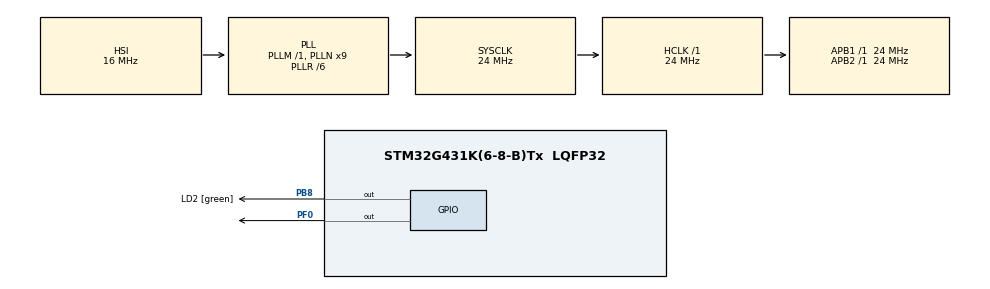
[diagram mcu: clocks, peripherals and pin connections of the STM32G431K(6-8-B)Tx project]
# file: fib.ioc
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Mcu.Family=STM32G4
Mcu.Name=STM32G431K(6-8-B)Tx
Mcu.Package=LQFP32
NVIC.PriorityGroup=NVIC_PRIORITYGROUP_4
NVIC.RTC_WKUP_IRQn=true\:0\:0\:false\:false\:true\:true\:true\:true
PA13.GPIO_Label=T_SWDIO
PA13.Mode=Serial_Wire
PA13.Signal=SYS_JTMS-SWDIO
PA14.GPIO_Label=T_SWCLK
PA14.Mode=Serial_Wire
PA14.Signal=SYS_JTCK-SWCLK
PA2.GPIO_Label=USART2_TX [ST-LINKV3E_VCP_RX]
PA2.Signal=USART2_TX
PA3.GPIO_Label=USART2_RX [ST-LINKV3E_VCP_TX]
PA3.Signal=USART2_RX
PB3.GPIO_Label=T_SWO
PB3.Signal=SYS_JTDO-SWO
PB8-BOOT0.GPIO_Label=LD2 [green]
PB8-BOOT0.Signal=GPIO_Output
PF0-OSC_IN.Signal=GPIO_Output
ProjectManager.HeapSize=0x200
ProjectManager.StackSize=0x400
ProjectManager.TargetToolchain=STM32CubeIDE
RCC.ADC12Freq_Value=24000000
RCC.AHBFreq_Value=24000000
RCC.APB1Freq_Value=24000000
RCC.APB1TimFreq_Value=24000000
RCC.APB2Freq_Value=24000000
RCC.APB2TimFreq_Value=24000000
RCC.CortexFreq_Value=24000000
RCC.EXTERNAL_CLOCK_VALUE=12288000
RCC.HCLKFreq_Value=24000000
RCC.HSE_VALUE=8000000
RCC.HSI48_VALUE=48000000
RCC.HSI_VALUE=16000000
RCC.LSE_VALUE=32768
RCC.PLLN=9
RCC.PLLR=RCC_PLLR_DIV6
RCC.SYSCLKFreq_VALUE=24000000
RCC.SYSCLKSource=RCC_SYSCLKSOURCE_PLLCLK
RCC.USBFreq_Value=72000000
RCC.VCOOutputFreq_Value=144000000
VP_RTC_VS_RTC_Activate.Mode=RTC_Enabled
VP_RTC_VS_RTC_WakeUp_intern.Mode=WakeUp
board=NUCLEO-G431KB

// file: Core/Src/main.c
/* USER CODE BEGIN Header */
/**
  ******************************************************************************
  * @file           : main.c
  * @brief          : Main program body
  ******************************************************************************
  * @attention
  *
  * Copyright (c) 2023 STMicroelectronics.
  * All rights reserved.
  *
  * This software is licensed under terms that can be found in the LICENSE file
  * in the root directory of this software component.
  * If no LICENSE file comes with this software, it is provided AS-IS.
  *
  ******************************************************************************
  */
/* USER CODE END Header */
#include "main.h"

RTC_HandleTypeDef hrtc;

void SystemClock_Config(void);
static void MX_GPIO_Init(void);
static void MX_RTC_Init(void);
/* USER CODE BEGIN PFP */
void SystemClock_Config170MHZ(void);
void SystemClock_Config150MHZ(void);
/* USER CODE END PFP */

/* USER CODE BEGIN 0 */

/*
void Sleep(int time)
{
    HAL_SuspendTick();
    uint32_t counter = time*2;
    HAL_RTCEx_SetWakeUpTimer_IT(&hrtc, counter, RTC_WAKEUPCLOCK_RTCCLK_DIV16);
    HAL_PWR_EnterSLEEPMode(PWR_MAINREGULATOR_ON, PWR_STOPENTRY_WFI);
    HAL_RTCEx_DeactivateWakeUpTimer(&hrtc);
    HAL_ResumeTick();
}*/

void EnterSleep()
{
    HAL_SuspendTick();
    HAL_PWR_EnterSLEEPMode(PWR_MAINREGULATOR_ON, PWR_STOPENTRY_WFI);
}

void fibonacci(unsigned int n)  {
    unsigned long long a = 0;
    unsigned long long b = 1;
    unsigned long long fib;

    for (unsigned int i = 2; i <= n; ++i) {
        fib = a + b;
        a = b;
        b = fib;
    }
}

__attribute__((section(".ccmram")))
void fibonacci_ccm(unsigned int n)  {
    unsigned long long a = 0;
    unsigned long long b = 1;
    unsigned long long fib;

    for (unsigned int i = 2; i <= n; ++i) {
        fib = a + b;
        a = b;
        b = fib;
    }
}

void Sleep(int time)
{
  HAL_SuspendTick();
  uint32_t counter = time*2;/*divide by (16/32)*/
  HAL_RTCEx_SetWakeUpTimer_IT(&hrtc, counter, RTC_WAKEUPCLOCK_RTCCLK_DIV16);

  /* Enter sleep mode */
  HAL_PWR_EnterSLEEPMode(PWR_MAINREGULATOR_ON, PWR_STOPENTRY_WFI);
  HAL_RTCEx_DeactivateWakeUpTimer(&hrtc);
  HAL_ResumeTick();
}
/* USER CODE END 0 */

int main(void)
{

  /* MCU Configuration--------------------------------------------------------*/

  /* Reset of all peripherals, Initializes the Flash interface and the Systick. */
  HAL_Init();

  /* Configure the system clock */
  SystemClock_Config();

  /* Initialize all configured peripherals */
  MX_GPIO_Init();
  MX_RTC_Init();

  /* Infinite loop */
  /* USER CODE BEGIN WHILE */
  int n = 500000;
  Sleep(500);
  fibonacci(n);
  Sleep(500);
  fibonacci_ccm(n);
  EnterSleep();

  /* USER CODE BEGIN SysInit */

  /* USER CODE END SysInit */

  /* Initialize all configured peripherals */

  /* USER CODE BEGIN 2 */
  /* USER CODE END 2 */

  /* Infinite loop */
  /* USER CODE BEGIN WHILE */

    /* USER CODE END WHILE */

}

void SystemClock_Config(void)
{
  RCC_OscInitTypeDef RCC_OscInitStruct = {0};
  RCC_ClkInitTypeDef RCC_ClkInitStruct = {0};

  /** Configure the main internal regulator output voltage
  */
  HAL_PWREx_ControlVoltageScaling(PWR_REGULATOR_VOLTAGE_SCALE1);

  /** Initializes the RCC Oscillators according to the specified parameters
  * in the RCC_OscInitTypeDef structure.
  */
  RCC_OscInitStruct.OscillatorType = RCC_OSCILLATORTYPE_HSI|RCC_OSCILLATORTYPE_LSI;
  RCC_OscInitStruct.HSIState = RCC_HSI_ON;
  RCC_OscInitStruct.HSICalibrationValue = RCC_HSICALIBRATION_DEFAULT;
  RCC_OscInitStruct.LSIState = RCC_LSI_ON;
  RCC_OscInitStruct.PLL.PLLState = RCC_PLL_ON;
  RCC_OscInitStruct.PLL.PLLSource = RCC_PLLSOURCE_HSI;
  RCC_OscInitStruct.PLL.PLLM = RCC_PLLM_DIV1;
  RCC_OscInitStruct.PLL.PLLN = 9;
  RCC_OscInitStruct.PLL.PLLP = RCC_PLLP_DIV2;
  RCC_OscInitStruct.PLL.PLLQ = RCC_PLLQ_DIV2;
  RCC_OscInitStruct.PLL.PLLR = RCC_PLLR_DIV6;
  if (HAL_RCC_OscConfig(&RCC_OscInitStruct) != HAL_OK)
  {
    Error_Handler();
  }

  /** Initializes the CPU, AHB and APB buses clocks
  */
  RCC_ClkInitStruct.ClockType = RCC_CLOCKTYPE_HCLK|RCC_CLOCKTYPE_SYSCLK
                              |RCC_CLOCKTYPE_PCLK1|RCC_CLOCKTYPE_PCLK2;
  RCC_ClkInitStruct.SYSCLKSource = RCC_SYSCLKSOURCE_PLLCLK;
  RCC_ClkInitStruct.AHBCLKDivider = RCC_SYSCLK_DIV1;
  RCC_ClkInitStruct.APB1CLKDivider = RCC_HCLK_DIV1;
  RCC_ClkInitStruct.APB2CLKDivider = RCC_HCLK_DIV1;

  if (HAL_RCC_ClockConfig(&RCC_ClkInitStruct, FLASH_LATENCY_0) != HAL_OK)
  {
    Error_Handler();
  }
}

static void MX_RTC_Init(void)
{

  /** Initialize RTC Only
  */
  hrtc.Instance = RTC;
  hrtc.Init.HourFormat = RTC_HOURFORMAT_24;
  hrtc.Init.AsynchPrediv = 127;
  hrtc.Init.SynchPrediv = 255;
  hrtc.Init.OutPut = RTC_OUTPUT_DISABLE;
  hrtc.Init.OutPutRemap = RTC_OUTPUT_REMAP_NONE;
  hrtc.Init.OutPutPolarity = RTC_OUTPUT_POLARITY_HIGH;
  hrtc.Init.OutPutType = RTC_OUTPUT_TYPE_OPENDRAIN;
  hrtc.Init.OutPutPullUp = RTC_OUTPUT_PULLUP_NONE;
  if (HAL_RTC_Init(&hrtc) != HAL_OK)
  {
    Error_Handler();
  }

  /** Enable the WakeUp
  */
  if (HAL_RTCEx_SetWakeUpTimer_IT(&hrtc, 0, RTC_WAKEUPCLOCK_RTCCLK_DIV16) != HAL_OK)
  {
    Error_Handler();
  }

}

static void MX_GPIO_Init(void)
{
  GPIO_InitTypeDef GPIO_InitStruct = {0};

  /* GPIO Ports Clock Enable */
  __HAL_RCC_GPIOF_CLK_ENABLE();
  __HAL_RCC_GPIOG_CLK_ENABLE();
  __HAL_RCC_GPIOA_CLK_ENABLE();
  __HAL_RCC_GPIOB_CLK_ENABLE();

  /*Configure GPIO pin Output Level */
  HAL_GPIO_WritePin(GPIOF, GPIO_PIN_0, GPIO_PIN_RESET);

  /*Configure GPIO pin Output Level */
  HAL_GPIO_WritePin(LD2_GPIO_Port, LD2_Pin, GPIO_PIN_RESET);

  /*Configure GPIO pin : PF0 */
  GPIO_InitStruct.Pin = GPIO_PIN_0;
  GPIO_InitStruct.Mode = GPIO_MODE_OUTPUT_PP;
  GPIO_InitStruct.Pull = GPIO_NOPULL;
  GPIO_InitStruct.Speed = GPIO_SPEED_FREQ_LOW;
  HAL_GPIO_Init(GPIOF, &GPIO_InitStruct);

  /*Configure GPIO pin : PF1 */
  GPIO_InitStruct.Pin = GPIO_PIN_1;
  GPIO_InitStruct.Mode = GPIO_MODE_ANALOG;
  GPIO_InitStruct.Pull = GPIO_NOPULL;
  HAL_GPIO_Init(GPIOF, &GPIO_InitStruct);

  /*Configure GPIO pin : PG10 */
  GPIO_InitStruct.Pin = GPIO_PIN_10;
  GPIO_InitStruct.Mode = GPIO_MODE_ANALOG;
  GPIO_InitStruct.Pull = GPIO_NOPULL;
  HAL_GPIO_Init(GPIOG, &GPIO_InitStruct);

  /*Configure GPIO pins : PA0 PA1 PA4 PA5
                           PA6 PA7 PA8 PA9
                           PA10 PA11 PA12 PA15 */
  GPIO_InitStruct.Pin = GPIO_PIN_0|GPIO_PIN_1|GPIO_PIN_4|GPIO_PIN_5
                          |GPIO_PIN_6|GPIO_PIN_7|GPIO_PIN_8|GPIO_PIN_9
                          |GPIO_PIN_10|GPIO_PIN_11|GPIO_PIN_12|GPIO_PIN_15;
  GPIO_InitStruct.Mode = GPIO_MODE_ANALOG;
  GPIO_InitStruct.Pull = GPIO_NOPULL;
  HAL_GPIO_Init(GPIOA, &GPIO_InitStruct);

  /*Configure GPIO pins : USART2_TX_Pin USART2_RX_Pin */
  GPIO_InitStruct.Pin = USART2_TX_Pin|USART2_RX_Pin;
  GPIO_InitStruct.Mode = GPIO_MODE_AF_PP;
  GPIO_InitStruct.Pull = GPIO_NOPULL;
  GPIO_InitStruct.Speed = GPIO_SPEED_FREQ_LOW;
  GPIO_InitStruct.Alternate = GPIO_AF7_USART2;
  HAL_GPIO_Init(GPIOA, &GPIO_InitStruct);

  /*Configure GPIO pins : PB0 PB4 PB5 PB6
                           PB7 */
  GPIO_InitStruct.Pin = GPIO_PIN_0|GPIO_PIN_4|GPIO_PIN_5|GPIO_PIN_6
                          |GPIO_PIN_7;
  GPIO_InitStruct.Mode = GPIO_MODE_ANALOG;
  GPIO_InitStruct.Pull = GPIO_NOPULL;
  HAL_GPIO_Init(GPIOB, &GPIO_InitStruct);

  /*Configure GPIO pin : LD2_Pin */
  GPIO_InitStruct.Pin = LD2_Pin;
  GPIO_InitStruct.Mode = GPIO_MODE_OUTPUT_PP;
  GPIO_InitStruct.Pull = GPIO_NOPULL;
  GPIO_InitStruct.Speed = GPIO_SPEED_FREQ_LOW;
  HAL_GPIO_Init(LD2_GPIO_Port, &GPIO_InitStruct);

}

/* USER CODE BEGIN 4 */
void SystemClock_Config170MHZ(void)
{
  RCC_OscInitTypeDef RCC_OscInitStruct = {0};
  RCC_ClkInitTypeDef RCC_ClkInitStruct = {0};

  /** Configure the main internal regulator output voltage
  */
  HAL_PWREx_ControlVoltageScaling(PWR_REGULATOR_VOLTAGE_SCALE1_BOOST);

  /** Initializes the RCC Oscillators according to the specified parameters
  * in the RCC_OscInitTypeDef structure.
  */
  RCC_OscInitStruct.OscillatorType = RCC_OSCILLATORTYPE_HSI;
  RCC_OscInitStruct.HSIState = RCC_HSI_ON;
  RCC_OscInitStruct.HSICalibrationValue = RCC_HSICALIBRATION_DEFAULT;
  RCC_OscInitStruct.PLL.PLLState = RCC_PLL_ON;
  RCC_OscInitStruct.PLL.PLLSource = RCC_PLLSOURCE_HSI;
  RCC_OscInitStruct.PLL.PLLM = RCC_PLLM_DIV4;
  RCC_OscInitStruct.PLL.PLLN = 85;
  RCC_OscInitStruct.PLL.PLLP = RCC_PLLP_DIV2;
  RCC_OscInitStruct.PLL.PLLQ = RCC_PLLQ_DIV2;
  RCC_OscInitStruct.PLL.PLLR = RCC_PLLR_DIV2;
  if (HAL_RCC_OscConfig(&RCC_OscInitStruct) != HAL_OK)
  {
    Error_Handler();
  }

  /** Initializes the CPU, AHB and APB buses clocks
  */
  RCC_ClkInitStruct.ClockType = RCC_CLOCKTYPE_HCLK|RCC_CLOCKTYPE_SYSCLK
                              |RCC_CLOCKTYPE_PCLK1|RCC_CLOCKTYPE_PCLK2;
  RCC_ClkInitStruct.SYSCLKSource = RCC_SYSCLKSOURCE_PLLCLK;
  RCC_ClkInitStruct.AHBCLKDivider = RCC_SYSCLK_DIV1;
  RCC_ClkInitStruct.APB1CLKDivider = RCC_HCLK_DIV1;
  RCC_ClkInitStruct.APB2CLKDivider = RCC_HCLK_DIV1;

  if (HAL_RCC_ClockConfig(&RCC_ClkInitStruct, FLASH_LATENCY_4) != HAL_OK)
  {
    Error_Handler();
  }
}

void SystemClock_Config150MHZ(void)
{
  RCC_OscInitTypeDef RCC_OscInitStruct = {0};
  RCC_ClkInitTypeDef RCC_ClkInitStruct = {0};

  /** Configure the main internal regulator output voltage
  */
  HAL_PWREx_ControlVoltageScaling(PWR_REGULATOR_VOLTAGE_SCALE1);

  /** Initializes the RCC Oscillators according to the specified parameters
  * in the RCC_OscInitTypeDef structure.
  */
  RCC_OscInitStruct.OscillatorType = RCC_OSCILLATORTYPE_HSI|RCC_OSCILLATORTYPE_LSI;
  RCC_OscInitStruct.HSIState = RCC_HSI_ON;
  RCC_OscInitStruct.HSICalibrationValue = RCC_HSICALIBRATION_DEFAULT;
  RCC_OscInitStruct.LSIState = RCC_LSI_ON;
  RCC_OscInitStruct.PLL.PLLState = RCC_PLL_ON;
  RCC_OscInitStruct.PLL.PLLSource = RCC_PLLSOURCE_HSI;
  RCC_OscInitStruct.PLL.PLLM = RCC_PLLM_DIV4;
  RCC_OscInitStruct.PLL.PLLN = 75;
  RCC_OscInitStruct.PLL.PLLP = RCC_PLLP_DIV2;
  RCC_OscInitStruct.PLL.PLLQ = RCC_PLLQ_DIV2;
  RCC_OscInitStruct.PLL.PLLR = RCC_PLLR_DIV2;
  if (HAL_RCC_OscConfig(&RCC_OscInitStruct) != HAL_OK)
  {
    Error_Handler();
  }

  /** Initializes the CPU, AHB and APB buses clocks
  */
  RCC_ClkInitStruct.ClockType = RCC_CLOCKTYPE_HCLK|RCC_CLOCKTYPE_SYSCLK
                              |RCC_CLOCKTYPE_PCLK1|RCC_CLOCKTYPE_PCLK2;
  RCC_ClkInitStruct.SYSCLKSource = RCC_SYSCLKSOURCE_PLLCLK;
  RCC_ClkInitStruct.AHBCLKDivider = RCC_SYSCLK_DIV1;
  RCC_ClkInitStruct.APB1CLKDivider = RCC_HCLK_DIV1;
  RCC_ClkInitStruct.APB2CLKDivider = RCC_HCLK_DIV1;

  if (HAL_RCC_ClockConfig(&RCC_ClkInitStruct, FLASH_LATENCY_4) != HAL_OK)
  {
    Error_Handler();
  }
}
/* USER CODE END 4 */

void Error_Handler(void)
{
  __disable_irq();
  while (1)
  {
  }
}
